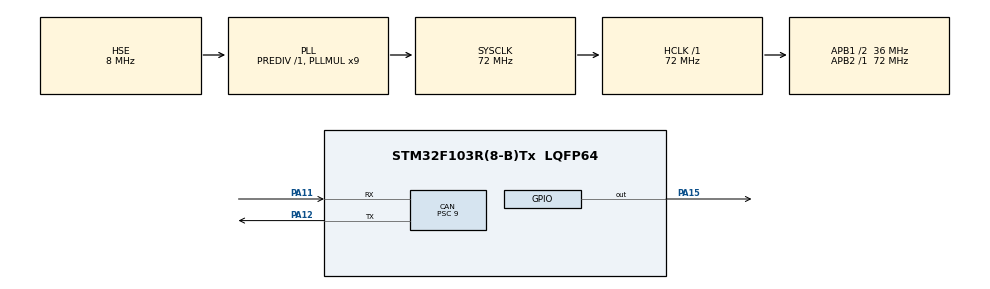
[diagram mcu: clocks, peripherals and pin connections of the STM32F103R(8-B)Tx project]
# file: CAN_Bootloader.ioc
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CAN.BS1=CAN_BS1_6TQ
CAN.CalculateBaudRate=500000
CAN.CalculateTimeBit=2000
CAN.CalculateTimeQuantum=250.0
CAN.NART=ENABLE
CAN.Prescaler=9
IWDG.Prescaler=IWDG_PRESCALER_8
Mcu.Family=STM32F1
Mcu.Name=STM32F103R(8-B)Tx
Mcu.Package=LQFP64
NVIC.CAN1_RX1_IRQn=true\:0\:0\:false\:false\:true\:true\:true\:true
NVIC.PriorityGroup=NVIC_PRIORITYGROUP_4
NVIC.USB_LP_CAN1_RX0_IRQn=true\:0\:0\:false\:false\:true\:true\:true\:true
PA11.Mode=CAN_Activate
PA11.Signal=CAN_RX
PA12.Mode=CAN_Activate
PA12.Signal=CAN_TX
PA13.Mode=Trace_Asynchronous_SW
PA13.Signal=SYS_JTMS-SWDIO
PA14.Mode=Trace_Asynchronous_SW
PA14.Signal=SYS_JTCK-SWCLK
PA15.Signal=GPIO_Output
PB3.Mode=Trace_Asynchronous_SW
PB3.Signal=SYS_JTDO-TRACESWO
PD0-OSC_IN.Mode=HSE-External-Oscillator
PD0-OSC_IN.Signal=RCC_OSC_IN
PD1-OSC_OUT.Mode=HSE-External-Oscillator
PD1-OSC_OUT.Signal=RCC_OSC_OUT
ProjectManager.HeapSize=0x200
ProjectManager.StackSize=0x400
ProjectManager.TargetToolchain=Makefile
RCC.AHBFreq_Value=72000000
RCC.APB1CLKDivider=RCC_HCLK_DIV2
RCC.APB1Freq_Value=36000000
RCC.APB1TimFreq_Value=72000000
RCC.APB2Freq_Value=72000000
RCC.APB2TimFreq_Value=72000000
RCC.HCLKFreq_Value=72000000
RCC.PLLMUL=RCC_PLL_MUL9
RCC.PLLSourceVirtual=RCC_PLLSOURCE_HSE
RCC.SYSCLKFreq_VALUE=72000000
RCC.SYSCLKSource=RCC_SYSCLKSOURCE_PLLCLK
RCC.USBFreq_Value=72000000
VP_CRC_VS_CRC.Mode=CRC_Activate
VP_IWDG_VS_IWDG.Mode=IWDG_Activate
board=custom

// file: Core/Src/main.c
/* USER CODE BEGIN Header */
/**
  ******************************************************************************
  * @file           : main.c
  * @brief          : Main program body
  ******************************************************************************
  * @attention
  *
  * Copyright (c) 2023 STMicroelectronics.
  * All rights reserved.
  *
  * This software is licensed under terms that can be found in the LICENSE file
  * in the root directory of this software component.
  * If no LICENSE file comes with this software, it is provided AS-IS.
  *
  ******************************************************************************
  */
/* USER CODE END Header */
#include "main.h"

/* USER CODE BEGIN Includes */
#include "version.h"
/* USER CODE END Includes */

CAN_HandleTypeDef hcan;

CRC_HandleTypeDef hcrc;

/* USER CODE BEGIN PV */

// 1 if a message has been received
volatile uint8_t message_received = 0;

/* USER CODE END PV */

void SystemClock_Config(void);
static void MX_GPIO_Init(void);
static void MX_CAN_Init(void);
static void MX_CRC_Init(void);

/* USER CODE BEGIN 0 */

//-----------------------------------------------------------------------------
//  Global variables
//-----------------------------------------------------------------------------

// time (in ms) of last can message. Used for bootloader timeout.
static volatile uint32_t lastcanrx;

//-----------------------------------------------------------------------------
//  utility functions
//-----------------------------------------------------------------------------

// Clock config that's almost a kilobyte(!) smaller than the CubeMX version.
// Shame it doesn't work
void configClocks(void)
{
  /* enable HSE */
  RCC->CR |= 0x00010001;
  while ((RCC->CR & 0x00020000) == 0)
    ; /* for it to come on */

  /* enable flash prefetch buffer */
  FLASH->ACR = 0x00000012;
  /* Configure PLL */
  RCC->CFGR |= 0x001D0400; /* pll=72Mhz,APB1/2=36Mhz,AHB=72Mhz */

  RCC->CR |= 0x01000000; /* enable the pll */
  while ((RCC->CR & 0x03000000) == 0)
    ; /* wait for it to come on */
  /* Set SYSCLK as PLL */
  RCC->CFGR |= 0x00000002;
  while ((RCC->CFGR & 0x00000008) == 0)
    ; /* wait for it to come on */
}

uint8_t __fls_wr(const uint32_t *page, const uint32_t *buf, uint32_t len)
{
  __HAL_FLASH_CLEAR_FLAG(FLASH_FLAG_EOP | FLASH_FLAG_PGERR | FLASH_FLAG_WRPERR);

  uint32_t erase_err;
  FLASH_EraseInitTypeDef erase_page = {
      FLASH_TYPEERASE_PAGES,
      FLASH_BANK_1,
      (uint32_t)page, 1};

  if (HAL_OK != HAL_FLASHEx_Erase(&erase_page, &erase_err))
  {
    return 1;
  }

  for (uint32_t i = 0; i < len; ++i)
  {
    if (HAL_OK != HAL_FLASH_Program(FLASH_TYPEPROGRAM_WORD, (uint32_t)page, *buf))
    {
      return 2;
    }
    ++page;
    ++buf;
  }

  return 0;
}

uint8_t fls_wr(const uint32_t *page, const uint32_t *buf, uint32_t len)
{
  // does flash equal buffer already?
  if (0 == memcmp(page, buf, 4 * len))
  {
    return 0;
  }

  HAL_FLASH_Unlock();
  uint8_t r = __fls_wr(page, buf, len);
  HAL_FLASH_Lock();
  if (r)
  {
    return r;
  }

  // verify
  if (0 != memcmp(page, buf, 4 * len))
  {
    return 10;
  }

  return 0;
}

void bl_tx_resp(uint8_t cmd, uint8_t ec)
{
  CAN_TxHeaderTypeDef m;
  m.IDE = CAN_ID_STD;
  m.StdId = CANID_BOOTLOADER_RPLY + FLASH_VARS->board.id;
  m.RTR = CAN_RTR_DATA;
  m.DLC = 3;
  uint8_t data[3];
  data[0] = FLASH_VARS->board.id;
  data[1] = cmd;
  data[2] = ec;
  uint32_t mailbox;
  volatile HAL_StatusTypeDef s = HAL_CAN_AddTxMessage(&hcan, &m, data, &mailbox);
  // Wait on TX message
  // while (HAL_CAN_IsTxMessagePending(&hcan, mailbox));
}

// Runs before any other code. Checks for magic value in memory from before bootloader reset
// and jumps to the app if it's present.
void PreSystemInit(void)
{
  // Check for magic value
  if (*(MAGIC_ADDR) == MAGIC_VAL)
  {
    // Magic value is present. Reset it then jump to app.
    *(MAGIC_ADDR) = 0;
    __set_MSP(*(APP_BASE));
    uint32_t app = *(APP_BASE + 1); // +1 = 4 bytes since uint32_t
    asm("bx %0\n" ::"r"(app)
        :);
  }
}

//-----------------------------------------------------------------------------
//  CAN msg processing
//-----------------------------------------------------------------------------

void process_can_msg(CAN_RxHeaderTypeDef *msg, uint8_t data[])
{
  static uint32_t pagebuf[PAGE_SIZE];

  if ((msg->StdId == CANID_BOOTLOADER_CMD) && (msg->DLC == 8))
  {
    struct bl_cmd_t blc;
    memcpy(&blc, data, 8);

    // All boards respond to ping command
    if (blc.cmd == BL_CMD_PING)
    {                                  // ping command - just respond with OK
      bl_tx_resp(blc.cmd, BL_SUCCESS); // OK
      return;
    }

    if (blc.brd != FLASH_VARS->board.id)
      return;
    message_received = 1;
    lastcanrx = HAL_GetTick();

    switch (blc.cmd)
    {
    case BL_CMD_WRITE_BUF: // write buffer command, par1 = offset, par2 =data
      if (blc.par1 < PAGE_SIZE)
      {
        pagebuf[blc.par1] = blc.par2;
        bl_tx_resp(blc.cmd, BL_SUCCESS); // OK
      }
      else
      {
        bl_tx_resp(blc.cmd, BL_ERR_INVALID_OFFSET); // invalid ofs
      }
      break;

    case BL_CMD_WRITE_PAGE: // write page command, par1 = page number, par2 = crc
      if (blc.par1 < PAGE_COUNT)
      {
        uint32_t crc = HAL_CRC_Calculate(&hcrc, pagebuf, PAGE_SIZE);
        if (crc == blc.par2)
        {
          uint32_t pgofs = blc.par1 * PAGE_SIZE;
          uint8_t r = fls_wr(APP_BASE + pgofs, pagebuf, PAGE_SIZE);
          if (r)
          {
            bl_tx_resp(blc.cmd, BL_ERR_FLASH_WRITE); // verify failed
          }
          else
          {
            bl_tx_resp(blc.cmd, BL_SUCCESS); // OK
          }
        }
        else
        {
          bl_tx_resp(blc.cmd, BL_ERR_INVALID_CRC); // invalid CRC
        }
      }
      else
      {
        bl_tx_resp(blc.cmd, BL_ERR_INVALID_PAGE_NUM); // invalid pagenum
      }
      break;

    case BL_CMD_WRITE_CRC: // write CRC command, par1 = number of pages, par2 = crc
      if (blc.par1 <= PAGE_COUNT)
      {
        uint32_t crc = HAL_CRC_Calculate(&hcrc, (uint32_t *)APP_BASE, blc.par1 * PAGE_SIZE);
        if (crc == blc.par2)
        {
          // New flash data to store
          struct bl_vars_t vars;
          // Update app data
          vars.app.page_count = blc.par1;
          vars.app.crc = blc.par2;

          // Keep board data
          vars.board = FLASH_VARS->board;

          uint8_t r = fls_wr(APP_BASE - PAGE_SIZE, (uint32_t *)&vars, sizeof(vars) / 4);
          if (r)
          {
            bl_tx_resp(blc.cmd, BL_ERR_FLASH_WRITE); // verify failed
          }
          else
          {
            bl_tx_resp(blc.cmd, BL_SUCCESS); // OK
          }
        }
        else
        {
          bl_tx_resp(blc.cmd, 2); // invalid CRC
        }
      }
      else
      {
        bl_tx_resp(blc.cmd, 1); // invalid number of pages
      }
      break;

    case BL_CMD_SET_ID: // Write ID command, par1 = new ID
      if (blc.par1 < 255 )
      {
        // Read data from flash
        struct bl_vars_t vars = *FLASH_VARS;
        // Update board ID
        vars.board.id = (uint8_t)blc.par1;

        uint8_t r = fls_wr(APP_BASE - PAGE_SIZE, (uint32_t *)&vars, sizeof(vars) / 4);
        if (r)
        {
          bl_tx_resp(blc.cmd, BL_ERR_FLASH_WRITE); // verify failed
        }
        else
        {
          bl_tx_resp(blc.cmd, BL_SUCCESS); // OK
        }
      }
      else
      {
        bl_tx_resp(blc.cmd, BL_ERR_INVALID_PAGE_NUM);
      }
      break;
    }
  }
}

void can_irq(CAN_HandleTypeDef *pcan)
{
  CAN_RxHeaderTypeDef msg;
  uint8_t data[8];
  HAL_CAN_GetRxMessage(pcan, CAN_RX_FIFO0, &msg, data);
  process_can_msg(&msg, data);
}

/* USER CODE END 0 */

int main(void)
{

  /* MCU Configuration--------------------------------------------------------*/

  /* Reset of all peripherals, Initializes the Flash interface and the Systick. */
  HAL_Init();

  /* Configure the system clock */
  SystemClock_Config();

  /* Initialize all configured peripherals */
  MX_GPIO_Init();
  MX_CAN_Init();
  MX_CRC_Init();
  /* USER CODE BEGIN 2 */

  // Check build ID in flashs
  if (BUILD_TIMESTAMP != FLASH_VARS->board.bl_build_version)
  {
    // Fresh BL build, reset FLASH_VARS
    struct bl_vars_t new_bl_vars = {0};
    new_bl_vars.board.bl_build_version = BUILD_TIMESTAMP;
    if (fls_wr(APP_BASE - PAGE_SIZE, (uint32_t *)&new_bl_vars, sizeof(new_bl_vars) / 4))
    {
      Error_Handler();
    }
  }

  /* USER CODE END 2 */

  /* Infinite loop */
  /* USER CODE BEGIN WHILE */
  while (1)
  {

    // reset if no CAN messages received
    uint32_t timeout;
    if (message_received)
      timeout = NOCANRX_TO;
    else
      timeout = STARTUP_TO;

    if (HAL_GetTick() - lastcanrx > timeout)
    {

      if ((FLASH_VARS->app.page_count > 0) && (FLASH_VARS->app.page_count <= PAGE_COUNT))
      {
        // Check app CRC before jumping to the app
        uint32_t crc = HAL_CRC_Calculate(&hcrc, (uint32_t *)APP_BASE, FLASH_VARS->app.page_count * PAGE_SIZE);
        if (crc == FLASH_VARS->app.crc)
        {
          *(MAGIC_ADDR) = MAGIC_VAL;
        }
      }
      // Reset the processor. If the magic value was set, the bootloader will be skipped, otherwise, the bootloader will restart.
      __NVIC_SystemReset();
    }

    // // feed watchdog // TODO Reenable
    HAL_IWDG_Refresh(&hiwdg);
    /* USER CODE END WHILE */

  }
}

void SystemClock_Config(void)
{
  RCC_OscInitTypeDef RCC_OscInitStruct = {0};
  RCC_ClkInitTypeDef RCC_ClkInitStruct = {0};

  /** Initializes the RCC Oscillators according to the specified parameters
  * in the RCC_OscInitTypeDef structure.
  */
  RCC_OscInitStruct.OscillatorType = RCC_OSCILLATORTYPE_HSE;
  RCC_OscInitStruct.HSEState = RCC_HSE_ON;
  RCC_OscInitStruct.HSEPredivValue = RCC_HSE_PREDIV_DIV1;
  RCC_OscInitStruct.HSIState = RCC_HSI_ON;
  RCC_OscInitStruct.PLL.PLLState = RCC_PLL_ON;
  RCC_OscInitStruct.PLL.PLLSource = RCC_PLLSOURCE_HSE;
  RCC_OscInitStruct.PLL.PLLMUL = RCC_PLL_MUL9;
  if (HAL_RCC_OscConfig(&RCC_OscInitStruct) != HAL_OK)
  {
    Error_Handler();
  }

  /** Initializes the CPU, AHB and APB buses clocks
  */
  RCC_ClkInitStruct.ClockType = RCC_CLOCKTYPE_HCLK|RCC_CLOCKTYPE_SYSCLK
                              |RCC_CLOCKTYPE_PCLK1|RCC_CLOCKTYPE_PCLK2;
  RCC_ClkInitStruct.SYSCLKSource = RCC_SYSCLKSOURCE_PLLCLK;
  RCC_ClkInitStruct.AHBCLKDivider = RCC_SYSCLK_DIV1;
  RCC_ClkInitStruct.APB1CLKDivider = RCC_HCLK_DIV2;
  RCC_ClkInitStruct.APB2CLKDivider = RCC_HCLK_DIV1;

  if (HAL_RCC_ClockConfig(&RCC_ClkInitStruct, FLASH_LATENCY_2) != HAL_OK)
  {
    Error_Handler();
  }
}

static void MX_CAN_Init(void)
{

  hcan.Instance = CAN1;
  hcan.Init.Prescaler = 9;
  hcan.Init.Mode = CAN_MODE_NORMAL;
  hcan.Init.SyncJumpWidth = CAN_SJW_1TQ;
  hcan.Init.TimeSeg1 = CAN_BS1_6TQ;
  hcan.Init.TimeSeg2 = CAN_BS2_1TQ;
  hcan.Init.TimeTriggeredMode = DISABLE;
  hcan.Init.AutoBusOff = DISABLE;
  hcan.Init.AutoWakeUp = DISABLE;
  hcan.Init.AutoRetransmission = ENABLE;
  hcan.Init.ReceiveFifoLocked = DISABLE;
  hcan.Init.TransmitFifoPriority = DISABLE;
  if (HAL_CAN_Init(&hcan) != HAL_OK)
  {
    Error_Handler();
  }
  /* USER CODE BEGIN CAN_Init 2 */
  // Accept all CAN messages
  CAN_FilterTypeDef sf;
  sf.FilterMaskIdHigh = 0x0000;
  sf.FilterMaskIdLow = 0x0000;
  sf.FilterFIFOAssignment = CAN_FILTER_FIFO0;
  sf.FilterBank = 0;
  sf.FilterMode = CAN_FILTERMODE_IDMASK;
  sf.FilterScale = CAN_FILTERSCALE_32BIT;
  sf.FilterActivation = CAN_FILTER_ENABLE;

  if (HAL_CAN_ConfigFilter(&hcan, &sf) != HAL_OK)
  {
    Error_Handler();
  }

  if (HAL_CAN_RegisterCallback(&hcan, HAL_CAN_RX_FIFO0_MSG_PENDING_CB_ID, can_irq))
  {
    Error_Handler();
  }

  if (HAL_CAN_Start(&hcan) != HAL_OK)
  {
    Error_Handler();
  }

  if (HAL_CAN_ActivateNotification(&hcan, CAN_IT_RX_FIFO0_MSG_PENDING) != HAL_OK)
  {
    Error_Handler();
  }
  /* USER CODE END CAN_Init 2 */

}

static void MX_CRC_Init(void)
{

  hcrc.Instance = CRC;
  if (HAL_CRC_Init(&hcrc) != HAL_OK)
  {
    Error_Handler();
  }

}

static void MX_GPIO_Init(void)
{
  GPIO_InitTypeDef GPIO_InitStruct = {0};

  /* GPIO Ports Clock Enable */
  __HAL_RCC_GPIOD_CLK_ENABLE();
  __HAL_RCC_GPIOA_CLK_ENABLE();
  __HAL_RCC_GPIOB_CLK_ENABLE();

  /*Configure GPIO pin Output Level */
  HAL_GPIO_WritePin(GPIOA, GPIO_PIN_15, GPIO_PIN_RESET);

  /*Configure GPIO pin : PA15 */
  GPIO_InitStruct.Pin = GPIO_PIN_15;
  GPIO_InitStruct.Mode = GPIO_MODE_OUTPUT_PP;
  GPIO_InitStruct.Pull = GPIO_NOPULL;
  GPIO_InitStruct.Speed = GPIO_SPEED_FREQ_LOW;
  HAL_GPIO_Init(GPIOA, &GPIO_InitStruct);

}

void Error_Handler(void)
{
  __disable_irq();
  while (1)
  {
  }
}
